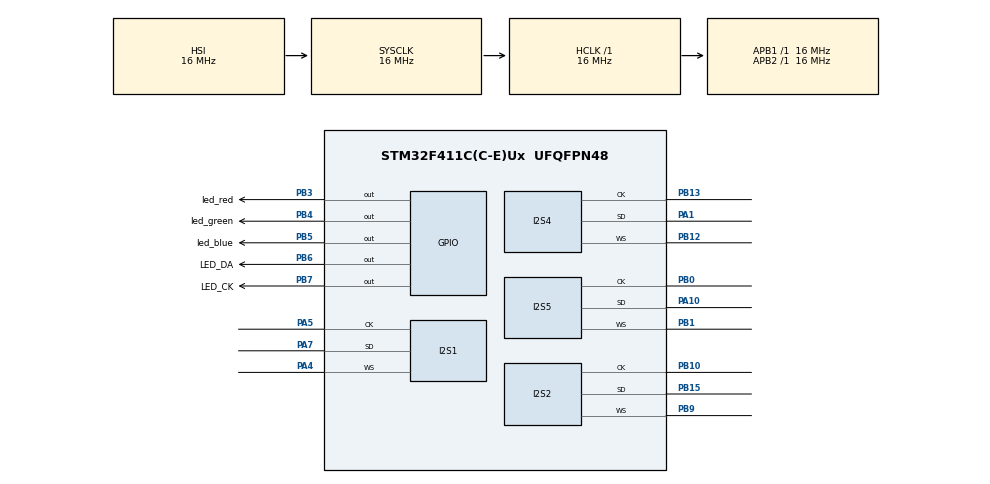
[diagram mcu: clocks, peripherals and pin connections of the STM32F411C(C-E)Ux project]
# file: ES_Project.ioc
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I2S1.ErrorAudioFreq=0.0 %
I2S1.FullDuplexMode=I2S_FULLDUPLEXMODE_DISABLE
I2S1.Instance=SPI$Index
I2S1.RealAudioFreq=8.0 KHz
I2S1.VirtualMode=I2S_MODE_MASTER
I2S2.ErrorAudioFreq=0.0 %
I2S2.FullDuplexMode=I2S_FULLDUPLEXMODE_DISABLE
I2S2.Instance=SPI$Index
I2S2.RealAudioFreq=8.0 KHz
I2S2.VirtualMode=I2S_MODE_MASTER
I2S4.ErrorAudioFreq=0.0 %
I2S4.FullDuplexMode=I2S_FULLDUPLEXMODE_DISABLE
I2S4.Instance=SPI$Index
I2S4.RealAudioFreq=8.0 KHz
I2S4.VirtualMode=I2S_MODE_MASTER
I2S5.ErrorAudioFreq=0.0 %
I2S5.FullDuplexMode=I2S_FULLDUPLEXMODE_DISABLE
I2S5.Instance=SPI$Index
I2S5.RealAudioFreq=8.0 KHz
I2S5.VirtualMode=I2S_MODE_MASTER
Mcu.Family=STM32F4
Mcu.Name=STM32F411C(C-E)Ux
Mcu.Package=UFQFPN48
NVIC.PriorityGroup=NVIC_PRIORITYGROUP_4
NVIC.TIM2_IRQn=true\:0\:0\:false\:false\:true\:true\:true\:true
PA1.Mode=Half_Duplex_Master
PA1.Signal=I2S4_SD
PA10.Mode=Half_Duplex_Master
PA10.Signal=I2S5_SD
PA13.Mode=Serial_Wire
PA13.Signal=SYS_JTMS-SWDIO
PA14.Mode=Serial_Wire
PA14.Signal=SYS_JTCK-SWCLK
PA4.Mode=Half_Duplex_Master
PA4.Signal=I2S1_WS
PA5.Mode=Half_Duplex_Master
PA5.Signal=I2S1_CK
PA7.Mode=Half_Duplex_Master
PA7.Signal=I2S1_SD
PB0.Mode=Half_Duplex_Master
PB0.Signal=I2S5_CK
PB1.Mode=Half_Duplex_Master
PB1.Signal=I2S5_WS
PB10.Mode=Half_Duplex_Master
PB10.Signal=I2S2_CK
PB12.Mode=Half_Duplex_Master
PB12.Signal=I2S4_WS
PB13.Mode=Half_Duplex_Master
PB13.Signal=I2S4_CK
PB15.Mode=Half_Duplex_Master
PB15.Signal=I2S2_SD
PB3.GPIO_Label=led_red
PB3.Signal=GPIO_Output
PB4.GPIO_Label=led_green
PB4.Signal=GPIO_Output
PB5.GPIO_Label=led_blue
PB5.Signal=GPIO_Output
PB6.GPIO_Label=LED_DA
PB6.Signal=GPIO_Output
PB7.GPIO_Label=LED_CK
PB7.Signal=GPIO_Output
PB9.Mode=Half_Duplex_Master
PB9.Signal=I2S2_WS
ProjectManager.HeapSize=0x200
ProjectManager.StackSize=0x400
ProjectManager.TargetToolchain=STM32CubeIDE
RCC.AHBFreq_Value=16000000
RCC.APB1Freq_Value=16000000
RCC.APB2Freq_Value=16000000
RCC.CortexFreq_Value=16000000
RCC.HSE_VALUE=25000000
RCC.HSI_VALUE=16000000
RCC.LSE_VALUE=32768
RCC.SYSCLKFreq_VALUE=16000000
RCC.VCOOutputFreq_Value=192000000
TIM2.Period=10 - 1
TIM2.Prescaler=16000 - 1
VP_TIM2_VS_ClockSourceINT.Mode=Internal
board=custom

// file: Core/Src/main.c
/* USER CODE BEGIN Header */
/**
  ******************************************************************************
  * @file           : main.c
  * @brief          : Main program body
  ******************************************************************************
  * @attention
  *
  * Copyright (c) 2024 STMicroelectronics.
  * All rights reserved.
  *
  * This software is licensed under terms that can be found in the LICENSE file
  * in the root directory of this software component.
  * If no LICENSE file comes with this software, it is provided AS-IS.
  *
  ******************************************************************************
  */
/* USER CODE END Header */
#include "main.h"

/* USER CODE BEGIN Includes */
#include "global.h"
/* USER CODE END Includes */

I2S_HandleTypeDef hi2s1;
I2S_HandleTypeDef hi2s2;
I2S_HandleTypeDef hi2s4;
I2S_HandleTypeDef hi2s5;

TIM_HandleTypeDef htim2;

void SystemClock_Config(void);
void PeriphCommonClock_Config(void);
static void MX_GPIO_Init(void);
static void MX_I2S1_Init(void);
static void MX_I2S2_Init(void);
static void MX_I2S4_Init(void);
static void MX_I2S5_Init(void);
static void MX_TIM2_Init(void);

int main(void)
{

  /* MCU Configuration--------------------------------------------------------*/

  /* Reset of all peripherals, Initializes the Flash interface and the Systick. */
  HAL_Init();

  /* USER CODE BEGIN Init */
  test_init();
  color_init();
  /* USER CODE END Init */

  /* Configure the system clock */
  SystemClock_Config();

/* Configure the peripherals common clocks */
  PeriphCommonClock_Config();

  /* Initialize all configured peripherals */
  MX_GPIO_Init();
  MX_I2S1_Init();
  MX_I2S2_Init();
  MX_I2S4_Init();
  MX_I2S5_Init();
  MX_TIM2_Init();
  /* USER CODE BEGIN 2 */
  HAL_TIM_Base_Start_IT(&htim2);
  /* USER CODE END 2 */

  /* Infinite loop */
  /* USER CODE BEGIN WHILE */
  test_init();
  while (1)
  {
	  test_RGB();
	  //test_led_array();
	  clock_led();
    /* USER CODE END WHILE */

  }
}

void SystemClock_Config(void)
{
  RCC_OscInitTypeDef RCC_OscInitStruct = {0};
  RCC_ClkInitTypeDef RCC_ClkInitStruct = {0};

  /** Macro to configure the PLL multiplication factor
  */
  __HAL_RCC_PLL_PLLM_CONFIG(16);

  /** Macro to configure the PLL clock source
  */
  __HAL_RCC_PLL_PLLSOURCE_CONFIG(RCC_PLLSOURCE_HSI);

  /** Configure the main internal regulator output voltage
  */
  __HAL_RCC_PWR_CLK_ENABLE();
  __HAL_PWR_VOLTAGESCALING_CONFIG(PWR_REGULATOR_VOLTAGE_SCALE1);

  /** Initializes the RCC Oscillators according to the specified parameters
  * in the RCC_OscInitTypeDef structure.
  */
  RCC_OscInitStruct.OscillatorType = RCC_OSCILLATORTYPE_HSI;
  RCC_OscInitStruct.HSIState = RCC_HSI_ON;
  RCC_OscInitStruct.HSICalibrationValue = RCC_HSICALIBRATION_DEFAULT;
  RCC_OscInitStruct.PLL.PLLState = RCC_PLL_NONE;
  RCC_OscInitStruct.PLL.PLLSource = RCC_PLLSOURCE_HSI;
  if (HAL_RCC_OscConfig(&RCC_OscInitStruct) != HAL_OK)
  {
    Error_Handler();
  }

  /** Initializes the CPU, AHB and APB buses clocks
  */
  RCC_ClkInitStruct.ClockType = RCC_CLOCKTYPE_HCLK|RCC_CLOCKTYPE_SYSCLK
                              |RCC_CLOCKTYPE_PCLK1|RCC_CLOCKTYPE_PCLK2;
  RCC_ClkInitStruct.SYSCLKSource = RCC_SYSCLKSOURCE_HSI;
  RCC_ClkInitStruct.AHBCLKDivider = RCC_SYSCLK_DIV1;
  RCC_ClkInitStruct.APB1CLKDivider = RCC_HCLK_DIV1;
  RCC_ClkInitStruct.APB2CLKDivider = RCC_HCLK_DIV1;

  if (HAL_RCC_ClockConfig(&RCC_ClkInitStruct, FLASH_LATENCY_0) != HAL_OK)
  {
    Error_Handler();
  }
}

void PeriphCommonClock_Config(void)
{
  RCC_PeriphCLKInitTypeDef PeriphClkInitStruct = {0};

  /** Initializes the peripherals clock
  */
  PeriphClkInitStruct.PeriphClockSelection = RCC_PERIPHCLK_I2S;
  PeriphClkInitStruct.PLLI2S.PLLI2SN = 192;
  PeriphClkInitStruct.PLLI2S.PLLI2SM = 16;
  PeriphClkInitStruct.PLLI2S.PLLI2SR = 2;
  if (HAL_RCCEx_PeriphCLKConfig(&PeriphClkInitStruct) != HAL_OK)
  {
    Error_Handler();
  }
}

static void MX_I2S1_Init(void)
{

  hi2s1.Instance = SPI1;
  hi2s1.Init.Mode = I2S_MODE_MASTER_TX;
  hi2s1.Init.Standard = I2S_STANDARD_PHILIPS;
  hi2s1.Init.DataFormat = I2S_DATAFORMAT_16B;
  hi2s1.Init.MCLKOutput = I2S_MCLKOUTPUT_DISABLE;
  hi2s1.Init.AudioFreq = I2S_AUDIOFREQ_8K;
  hi2s1.Init.CPOL = I2S_CPOL_LOW;
  hi2s1.Init.ClockSource = I2S_CLOCK_PLL;
  hi2s1.Init.FullDuplexMode = I2S_FULLDUPLEXMODE_DISABLE;
  if (HAL_I2S_Init(&hi2s1) != HAL_OK)
  {
    Error_Handler();
  }

}

static void MX_I2S2_Init(void)
{

  hi2s2.Instance = SPI2;
  hi2s2.Init.Mode = I2S_MODE_MASTER_TX;
  hi2s2.Init.Standard = I2S_STANDARD_PHILIPS;
  hi2s2.Init.DataFormat = I2S_DATAFORMAT_16B;
  hi2s2.Init.MCLKOutput = I2S_MCLKOUTPUT_DISABLE;
  hi2s2.Init.AudioFreq = I2S_AUDIOFREQ_8K;
  hi2s2.Init.CPOL = I2S_CPOL_LOW;
  hi2s2.Init.ClockSource = I2S_CLOCK_PLL;
  hi2s2.Init.FullDuplexMode = I2S_FULLDUPLEXMODE_DISABLE;
  if (HAL_I2S_Init(&hi2s2) != HAL_OK)
  {
    Error_Handler();
  }

}

static void MX_I2S4_Init(void)
{

  hi2s4.Instance = SPI4;
  hi2s4.Init.Mode = I2S_MODE_MASTER_TX;
  hi2s4.Init.Standard = I2S_STANDARD_PHILIPS;
  hi2s4.Init.DataFormat = I2S_DATAFORMAT_16B;
  hi2s4.Init.MCLKOutput = I2S_MCLKOUTPUT_DISABLE;
  hi2s4.Init.AudioFreq = I2S_AUDIOFREQ_8K;
  hi2s4.Init.CPOL = I2S_CPOL_LOW;
  hi2s4.Init.ClockSource = I2S_CLOCK_PLL;
  hi2s4.Init.FullDuplexMode = I2S_FULLDUPLEXMODE_DISABLE;
  if (HAL_I2S_Init(&hi2s4) != HAL_OK)
  {
    Error_Handler();
  }

}

static void MX_I2S5_Init(void)
{

  hi2s5.Instance = SPI5;
  hi2s5.Init.Mode = I2S_MODE_MASTER_TX;
  hi2s5.Init.Standard = I2S_STANDARD_PHILIPS;
  hi2s5.Init.DataFormat = I2S_DATAFORMAT_16B;
  hi2s5.Init.MCLKOutput = I2S_MCLKOUTPUT_DISABLE;
  hi2s5.Init.AudioFreq = I2S_AUDIOFREQ_8K;
  hi2s5.Init.CPOL = I2S_CPOL_LOW;
  hi2s5.Init.ClockSource = I2S_CLOCK_PLL;
  hi2s5.Init.FullDuplexMode = I2S_FULLDUPLEXMODE_DISABLE;
  if (HAL_I2S_Init(&hi2s5) != HAL_OK)
  {
    Error_Handler();
  }

}

static void MX_TIM2_Init(void)
{

  TIM_ClockConfigTypeDef sClockSourceConfig = {0};
  TIM_MasterConfigTypeDef sMasterConfig = {0};

  htim2.Instance = TIM2;
  htim2.Init.Prescaler = 16000 - 1;
  htim2.Init.CounterMode = TIM_COUNTERMODE_UP;
  htim2.Init.Period = 10 - 1;
  htim2.Init.ClockDivision = TIM_CLOCKDIVISION_DIV1;
  htim2.Init.AutoReloadPreload = TIM_AUTORELOAD_PRELOAD_DISABLE;
  if (HAL_TIM_Base_Init(&htim2) != HAL_OK)
  {
    Error_Handler();
  }
  sClockSourceConfig.ClockSource = TIM_CLOCKSOURCE_INTERNAL;
  if (HAL_TIM_ConfigClockSource(&htim2, &sClockSourceConfig) != HAL_OK)
  {
    Error_Handler();
  }
  sMasterConfig.MasterOutputTrigger = TIM_TRGO_RESET;
  sMasterConfig.MasterSlaveMode = TIM_MASTERSLAVEMODE_DISABLE;
  if (HAL_TIMEx_MasterConfigSynchronization(&htim2, &sMasterConfig) != HAL_OK)
  {
    Error_Handler();
  }

}

static void MX_GPIO_Init(void)
{
  GPIO_InitTypeDef GPIO_InitStruct = {0};

  /* GPIO Ports Clock Enable */
  __HAL_RCC_GPIOA_CLK_ENABLE();
  __HAL_RCC_GPIOB_CLK_ENABLE();

  /*Configure GPIO pin Output Level */
  HAL_GPIO_WritePin(GPIOB, led_red_Pin|led_green_Pin|led_blue_Pin|LED_DA_Pin
                          |LED_CK_Pin, GPIO_PIN_RESET);

  /*Configure GPIO pins : led_red_Pin led_green_Pin led_blue_Pin LED_DA_Pin
                           LED_CK_Pin */
  GPIO_InitStruct.Pin = led_red_Pin|led_green_Pin|led_blue_Pin|LED_DA_Pin
                          |LED_CK_Pin;
  GPIO_InitStruct.Mode = GPIO_MODE_OUTPUT_PP;
  GPIO_InitStruct.Pull = GPIO_NOPULL;
  GPIO_InitStruct.Speed = GPIO_SPEED_FREQ_LOW;
  HAL_GPIO_Init(GPIOB, &GPIO_InitStruct);

}

/* USER CODE BEGIN 4 */
void HAL_TIM_PeriodElapsedCallback(TIM_HandleTypeDef *htim)
{
	Run_timer();
	//getKeyInput();
}
/* USER CODE END 4 */

void Error_Handler(void)
{
  __disable_irq();
  while (1)
  {
  }
}
